# GAP8 register map
Vendor: GreenWaves Technologies SAS; Series: GAP8; File version: 1.3.1
CPU: other r1p0, little endian, MPU, no FPU, I-cache, DTCM, false interrupt priority bits
Registers are 32-bit, read-write, reset 0x0 unless marked. A register's access mark holds for its fields unless they carry their own. Offsets are from the block's base; [hi:lo] are bit positions; 'fields as' and 'values as' point back to an identical list.

## lvds — uDMA LVDS interface
Base 0x1A102000
0x00 rx_saddr — uDMA RX LVDS/ORCA buffer base address configuration register.
  [15:0] rx_saddr — RX buffer base address bitfield: - Read: returns value of the buffer pointer until transfer is finished. Else returns 0. - Write: sets RX buffer base address
0x04 rx_size — uDMA RX LVDS/ORCA buffer size configuration register.
  [16:0] rx_size — RX buffer size bitfield in bytes. (128kBytes maximum) - Read: returns remaining buffer size to transfer. - Write: sets buffer size.
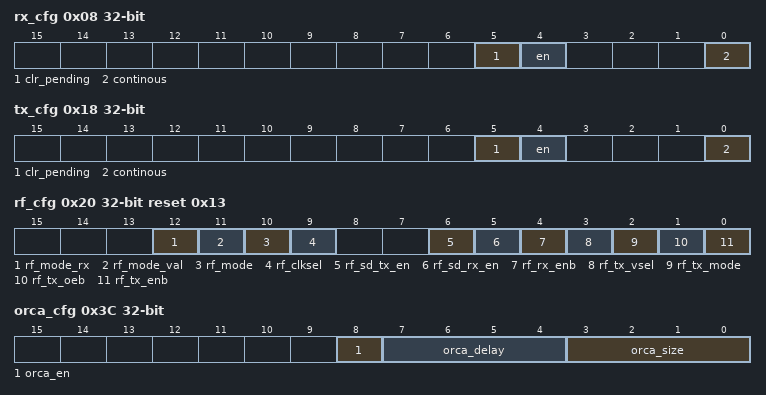
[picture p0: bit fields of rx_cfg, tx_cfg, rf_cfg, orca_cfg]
0x08 rx_cfg — uDMA RX LVDS/ORCA stream configuration register.
  [5] clr_pending — RX channel clear and stop transfer RX transfer pending in queue status flag
    on write: 0=disabled (no action); 1=stop and clear the on-going transfer | on read: 0=no pending transfer in the queue; 1=pending transfer in the queue
  [4] en — RX channel enable and start transfer bitfield This signal is used also to queue a transfer if one is already ongoing.
    0=disabled (feature is disabled); 1=start (enable and start the transfer)
  [0] continous — RX channel continuous mode bitfield At the end of the buffer transfer, the uDMA reloads the address / buffer size and starts a new transfer.
    0=disabled (feature is disabled); 1=enabled (feature is enabled)
0x10 tx_saddr — uDMA TX LVDS/ORCA buffer base address configuration register.
  [15:0] tx_saddr — TX buffer base address bitfield: - Read: returns value of the buffer pointer until transfer is finished. Else returns 0. - Write: sets buffer base address
0x14 tx_size — uDMA TX LVDS/ORCA buffer size configuration register.
  [16:0] tx_size — TX buffer size bitfield in bytes. (128kBytes maximum) - Read: returns remaining buffer size to transfer. - Write: sets buffer size.
0x18 tx_cfg — uDMA TX LVDS/ORCA stream configuration register.
  [5] clr_pending — TX channel clear and stop transfer bitfield TX transfer pending in queue status flag
    on write: 0=disabled (feature is disabled); 1=stop and clear the on-going transfer | on read: 0=no pending transfer in the queue; 1=pending transfer in the queue
  [4] en — TX channel enable and start transfer bitfield This signal is used also to queue a transfer if one is already ongoing.
    0=disabled (feature is disabled); 1=enable and start the transfer
  [0] continous — TX channel continuous mode bitfield At the end of the buffer transfer, the uDMA reloads the address / buffer size and starts a new transfer.
    values as rx_cfg.continous
0x20 rf_cfg reset 0x13 — uDMA LVDS configuration register.
  [12] rf_mode_rx — RX AT86RF215 synchronization bits detection bitfield
    0=enable (synchronization bits detection on the RxLVDS pad. The 2 bits of synchronization are on the 16bits MSB for I and Q of IQ data received.); 1=disable (potential of 16 bits data versus 13bits for AT86RF215 but synchronization to be managed by software)
  [11] rf_mode_val — TX set data bit0 value bitfield
    0=NO_IMMEDIATE_TX (set bit0 at 0, indicate AT86RF215 no immediate TX so TX is triggered by SPI command); 1=IMMEDIATE_TX (set bit0 at 1, indicate AT86RF215 immediate TX in case its register RF_IQIFC0.EEC(bit0)=1)
  [10] rf_mode — TX configuration specific to AT86RF215 bitfield
    0=enable (add synchronisation bits on bit15-14 and bit0 used for immediate TX, payload is on bits 13 to 1.); 1=disable (this means SW to manage synchronisation with the 16bits data to TX)
  [9] rf_clksel — CLK selection bitfield
    0=EXT_RX_CLK (use the external RX clk received by RX LVDS PAD); 1=SOC_CLK (use the SoC clk (useful for early functionality tests). For SoC clk availability, RF_CLKDIV_EN as to be 1(enabled) then the minimum clock ratio is divided by 2 if RF_CLKDIV_CFG is 0.)
  [6] rf_sd_tx_en — Enable TX serializer bitfield
    values as rx_cfg.continous
  [5] rf_sd_rx_en — Enable RX serdes bitfield
    values as rx_cfg.continous
  [4] rf_rx_enb — Enable RX LVDS PAD bitfield
    0=enabled (feature is enabled); 1=disabled (feature is disabled)
  [3] rf_tx_vsel — TX LVDS PAD Core voltage selector bitfield
    0=VDD_1_0V (if VDD=1.0V); 1=VDD_1_2V (if VDD=1.2V)
  [2] rf_tx_mode — TX LVDS PAD Current selector pin bitfield
    0=low_current (MODE = 0 selects low current); 1=high_current (MODE = 1 selects high current)
  [1] rf_tx_oeb — TX LVDS PAD Output Enable bitfield
    0=enable output; 1=disable output
  [0] rf_tx_enb — TX LVDS PAD Active-high power down mode select bitfield
    0=enable output; 1=disable output
0x28 rf_status ro — uDMA LVDS status register.
  [0] rf_sync_flag — Read only RX Synchronization flag between RX serdes block and the AT86RF215 bitfield: -1'b0 not synchonized -1'b1 synchonized - Rx serdes synchronized with external AT86RF215 synchronization
0x30 clkdiv_en — uDMA LVDS clock divider enable configuration register.
  [0] rf_clkdiv_en — Clock divider activation bitfield.
0x34 clkdiv_cfg — uDMA LVDS clock divider configuration register.
  [7:0] rf_clkdiv_cfg — Clock division ratio increased by power of 2 suite. 0 is divided by 2, 1 by 4, 2 by 8… 7 by 256
0x38 clkdiv_upd wo — uDMA LVDS clock divider update configuration register.
  [0] rf_clkdiv_upd — Apply effectively CLKDIV_CFG configuration
0x3C orca_cfg — uDMA ORCA configuration register.
  [8] orca_en — ORCA Channel enable and start transfer bitfield
    values as rx_cfg.continous
  [7:4] orca_delay — ORCA delay between first data to TXSYNC signal in cycle for TX bitfield (minimum 1 cycle delay). Default value is 0x0 for 1 cycle delay. 0X1 for 2 cycle delay etc.
  [3:0] orca_size — ORCA data size in bits bitfield (16Bits maximum).
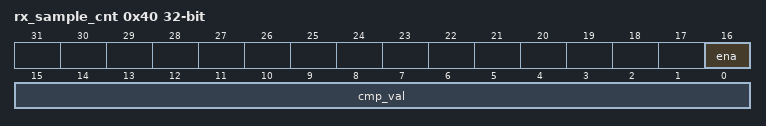
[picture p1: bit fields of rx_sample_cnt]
0x40 rx_sample_cnt — uDMA LVDS RX sample counter configuration register.
  [16] ena — LVDS event generation on compare match with CMP_VAL configuration bitfield
    values as rx_cfg.continous
  [15:0] cmp_val — LVDS RX sample comparison value configuration bitfield.
